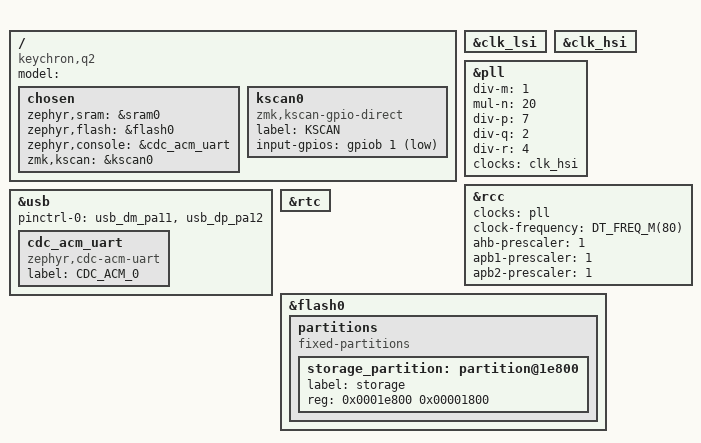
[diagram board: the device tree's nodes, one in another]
/*
 * Copyright (c) 2020 The ZMK Contributors
 *
 * SPDX-License-Identifier: MIT
 */

/dts-v1/;
#include <st/l4/stm32l432Xc.dtsi>
#include <st/l4/stm32l432k(b-c)ux-pinctrl.dtsi>

/ {
	model = "";
	compatible = "keychron,q2", "st,stm32l432";

	chosen {
		zephyr,sram = &sram0;
		zephyr,flash = &flash0;
		zephyr,console = &cdc_acm_uart;
		zmk,kscan = &kscan0;
	};

	kscan0: kscan0 {
		compatible = "zmk,kscan-gpio-direct";
		label = "KSCAN";

		input-gpios
			= <&gpiob 1 (GPIO_ACTIVE_LOW | GPIO_PULL_UP)>
			;
	};
};

&clk_lsi {
	status = "okay";
};

&clk_hsi {
	status = "okay";
};

&pll {
	div-m = <1>;
	mul-n = <20>;
	div-p = <7>;
	div-q = <2>;
	div-r = <4>;
	clocks = <&clk_hsi>;
	status = "okay";
};

&rcc {
	clocks = <&pll>;
	clock-frequency = <DT_FREQ_M(80)>;
	ahb-prescaler = <1>;
	apb1-prescaler = <1>;
	apb2-prescaler = <1>;
};

&usb {
	status = "okay";
	pinctrl-0 = <&usb_dm_pa11 &usb_dp_pa12>;
	pinctrl-names = "default";
	cdc_acm_uart: cdc_acm_uart {
		compatible = "zephyr,cdc-acm-uart";
		label = "CDC_ACM_0";
	};
};

&rtc {
	status = "okay";
};

&flash0 {
	/*
	 * For more information, see:
	 * http://docs.zephyrproject.org/latest/guides/dts/index.html#flash-partitions
	 */
	partitions {
		compatible = "fixed-partitions";
		#address-cells = <1>;
		#size-cells = <1>;

		/* Set 6Kb of storage at the end of the 128Kb of flash */
		storage_partition: partition@1e800 {
			label = "storage";
			reg = <0x0001e800 0x00001800>;
		};
	};
};
